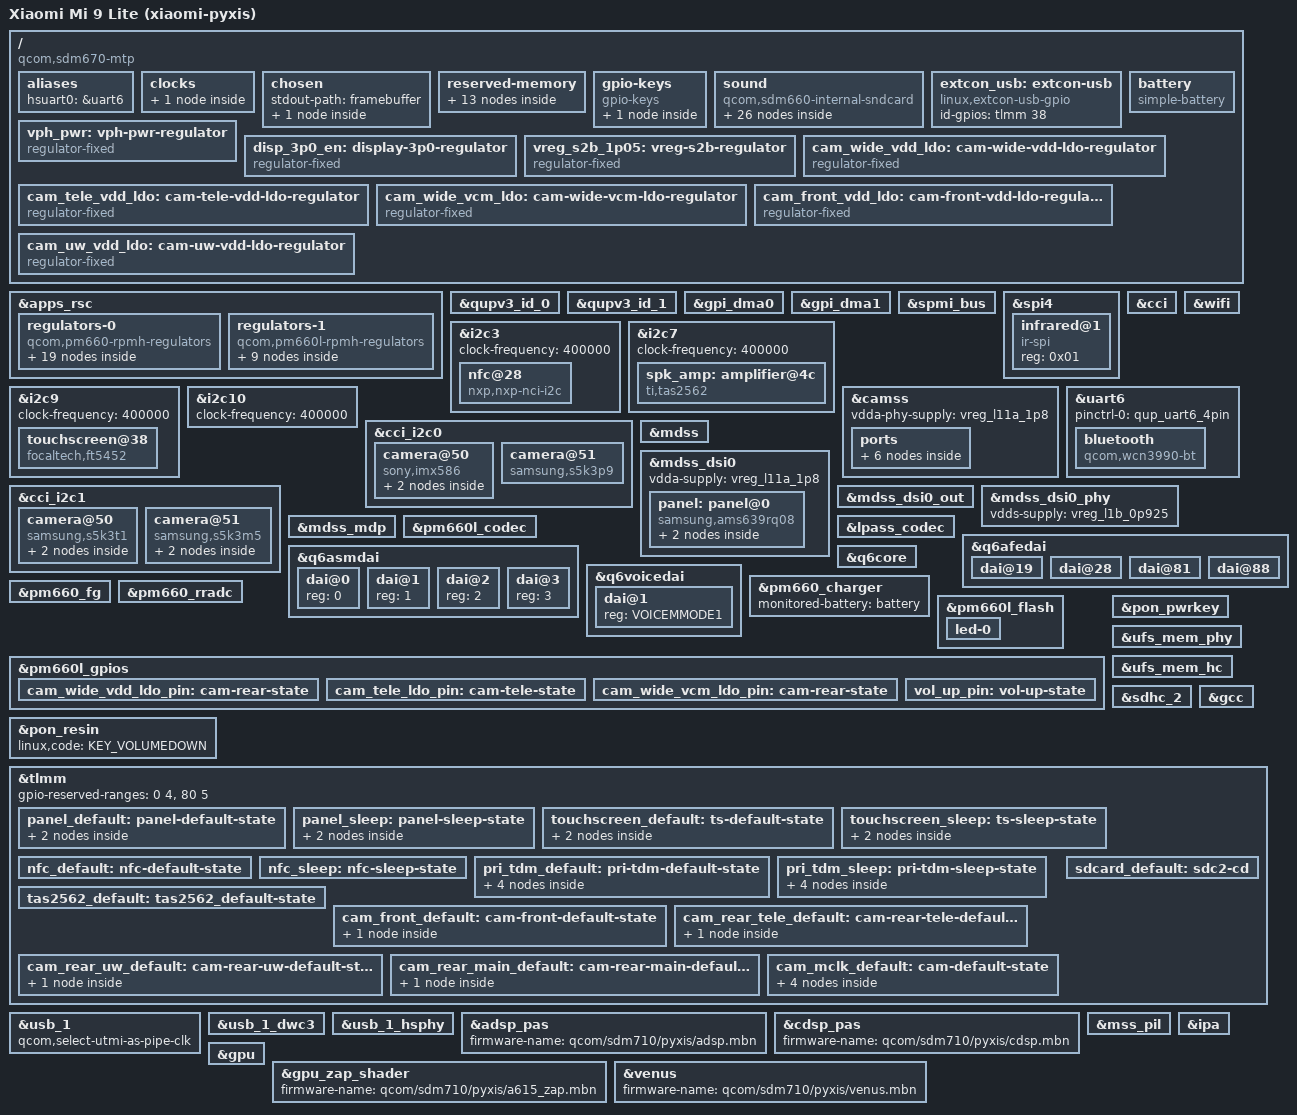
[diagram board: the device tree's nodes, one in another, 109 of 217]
// SPDX-License-Identifier: GPL-2.0
/*
 * Device tree for Xiaomi Mi 9 Lite (xiaomi-pyxis), based largely on
 * sdm670-google-sargo and downstream vendor kernel.
 *
 * Copyright (c) 2026, The Linux Foundation. All rights reserved.
*/

/dts-v1/;
#include <dt-bindings/firmware/qcom,scm.h>
#include <dt-bindings/gpio/gpio.h>
#include <dt-bindings/input/input.h>
#include <dt-bindings/leds/common.h>
#include <dt-bindings/pinctrl/qcom,pmic-gpio.h>
#include <dt-bindings/power/qcom-rpmpd.h>
#include <dt-bindings/sound/qcom,q6afe.h>
#include <dt-bindings/sound/qcom,q6asm.h>
#include <dt-bindings/sound/qcom,q6voice.h>
#include "sdm710.dtsi"
#include "pm660.dtsi"
#include "pm660l.dtsi"

/delete-node/ &xbl_mem;
/delete-node/ &wlan_msa_mem;
/delete-node/ &cdsp_mem;
/delete-node/ &mba_region;
/delete-node/ &adsp_mem;
/delete-node/ &ipa_fw_mem;
/delete-node/ &ipa_gsi_mem;
/delete-node/ &gpu_mem;
/delete-node/ &rmtfs_mem;

/ {
	model = "Xiaomi Mi 9 Lite (xiaomi-pyxis)";
	compatible = "qcom,sdm670-mtp", "qcom,sdm670", "qcom,mtp";
	qcom,msm-id = <0x360 0 393 0>;
	qcom,board-id = <35 0>;
	chassis-type = "handset";

	aliases {
		hsuart0 = &uart6;
	};

	clocks {
		int_cdc_bclk: int-cdc-bclk {
			compatible = "fixed-clock";
			#clock-cells = <0>;
			clock-frequency = <1536000>;
		};
	};

	chosen {
		stdout-path = "framebuffer";
		#address-cells = <2>;
		#size-cells = <2>;
		ranges;

		framebuffer: framebuffer@9c000000 {
			compatible = "simple-framebuffer";
			reg = <0 0x9c000000 0 (1080 * 2340 * 4)>;
			width = <1080>;
			height = <2340>;
			stride = <(1080 * 4)>;
			format = "a8r8g8b8";
			status = "okay";
		};
	};

	reserved-memory {
		#address-cells = <2>;
		#size-cells = <2>;

		xbl_mem: memory@85e00000 {
			reg = <0 0x85e00000 0 0x1c0000>;
			no-map;
		};

		// Looks like this is needed to avoid random crashes...
		removed_region: removed-region {
			reg = <0 0x85fc0000 0 0x4b40000>;
			no-map;
		};

		wlan_msa_mem: wlan-msa@93300000 {
			reg = <0 0x93300000 0 0x100000>;
			no-map;
		};

		cdsp_mem: cdsp@93400000 {
			reg = <0 0x93400000 0 0x1e00000>;
			no-map;
		};

		mba_region: mba@95200000 {
			reg = <0 0x95200000 0 0x200000>;
			no-map;
		};

		adsp_mem: adsp@95400000 {
			reg = <0 0x95400000 0 0x2200000>;
			no-map;
		};

		ipa_fw_mem: ipa-fw@97600000 {
			reg = <0 0x97600000 0 0x10000>;
			no-map;
		};

		ipa_gsi_mem: ipa-gsi@97610000 {
			reg = <0 0x97610000 0 0x5000>;
			no-map;
		};

		gpu_mem: gpu@97615000 {
			reg = <0 0x97615000 0 0x2000>;
			no-map;
		};

		fb_mem: framebuffer@9c000000 {
			reg = <0 0x9c000000 0 0x2300000>;
			no-map;
		};

		rmtfs_lower_guard: rmtfs-lower-guard@fc200000 {
			reg = <0 0xfc200000 0 0x1000>;
			no-map;
		};

		rmtfs_mem: rmtfs-mem@fc201000 {
			compatible = "qcom,rmtfs-mem";
			reg = <0 0xfc201000 0 0x200000>;
			no-map;
			qcom,client-id = <1>;
			qcom,vmid = <QCOM_SCM_VMID_MSS_MSA>;
		};

		rmtfs_upper_guard: rmtfs-upper-guard@fc401000 {
			reg = <0 0xfc401000 0 0x1000>;
			no-map;
		};
	};

	gpio-keys {
		compatible = "gpio-keys";
		autorepeat;

		pinctrl-names = "default";
		pinctrl-0 = <&vol_up_pin>;

		key-vol-up {
			label = "Volume Up";
			linux,code = <KEY_VOLUMEUP>;
			gpios = <&pm660l_gpios 7 GPIO_ACTIVE_LOW>;
		};
	};

	// AUDIO: WIP
	sound: sound {
		compatible = "qcom,sdm660-internal-sndcard";
		model = "Xiaomi Mi 9 Lite";

		pinctrl-names = "default";
		pinctrl-0 = <&cdc_pdm_default>,
			<&cdc_dmic_default>,
			<&pri_tdm_default>;

		audio-routing = "Analog PDM_RX1", "Digital PDM_RX1",
			"Analog PDM_RX2", "Digital PDM_RX2",
			"Analog PDM_RX3", "Digital PDM_RX3",
			"Digital LPASS_PDM_TX", "Analog PDM_TX",
			"Analog AMIC2", "Analog MIC BIAS External2",
			"Stereo1 DMIC Mux", "Analog MIC BIAS Internal1";

		mm1-dai-link {
			link-name = "MultiMedia1";

			cpu {
				sound-dai = <&q6asmdai MSM_FRONTEND_DAI_MULTIMEDIA1>;
			};
		};

		mm2-dai-link {
			link-name = "MultiMedia2";

			cpu {
				sound-dai = <&q6asmdai MSM_FRONTEND_DAI_MULTIMEDIA2>;
			};
		};

		mm3-dai-link {
			link-name = "MultiMedia3";

			cpu {
				sound-dai = <&q6asmdai MSM_FRONTEND_DAI_MULTIMEDIA3>;
			};
		};

		mm4-dai-link {
			link-name = "MultiMedia4";

			cpu {
				sound-dai = <&q6asmdai MSM_FRONTEND_DAI_MULTIMEDIA4>;
			};
		};

		voicemmode1-dai-link {
			link-name = "VoiceMMode1";

			cpu {
				sound-dai = <&q6voicedai VOICEMMODE1>;
			};
		};

		pri-tdm-tx-link {
			link-name = "Primary TDM0 Capture";

			cpu {
				sound-dai = <&q6afedai PRIMARY_TDM_TX_0>;
			};

			platform {
				sound-dai = <&q6routing>;
			};

			codec {
				sound-dai = <&spk_amp 0>;
			};
		};

		sec-tdm-rx-link {
			link-name = "Secondary TDM0 Playback";

			cpu {
				sound-dai = <&q6afedai SECONDARY_TDM_RX_0>;
			};

			platform {
				sound-dai = <&q6routing>;
			};

			codec {
				sound-dai = <&spk_amp 0>;
			};
		};

		int0-mi2s-rx-link {
			link-name = "Internal MI2S Playback";

			cpu {
				sound-dai = <&q6afedai INT0_MI2S_RX>;
			};

			platform {
				sound-dai = <&q6routing>;
			};

			codec {
				sound-dai = <&pm660l_codec 0>, <&lpass_codec 0>;
			};
		};

		int3-mi2s-tx-link {
				link-name = "Internal MI2S Capture";

			cpu {
				sound-dai = <&q6afedai INT3_MI2S_TX>;
			};

			platform {
				sound-dai = <&q6routing>;
			};

			codec {
				sound-dai = <&pm660l_codec 1>, <&lpass_codec 1>;
			};
		};
};

	extcon_usb: extcon-usb {
		compatible = "linux,extcon-usb-gpio";
		id-gpios = <&tlmm 38 GPIO_ACTIVE_HIGH>;
	};

	battery: battery {
		compatible = "simple-battery";
		voltage-min-design-microvolt = <3312000>;
		voltage-max-design-microvolt = <4400000>;
	};

	/* Regulators */
	vph_pwr: vph-pwr-regulator {
		compatible = "regulator-fixed";
		regulator-name = "vph_pwr";
		regulator-min-microvolt = <3312000>;
		regulator-max-microvolt = <3312000>;
		regulator-always-on;
		regulator-boot-on;
	};

	disp_3p0_en: display-3p0-regulator {
		compatible = "regulator-fixed";
		regulator-name = "disp_3p0_en";
		gpios = <&tlmm 76 GPIO_ACTIVE_HIGH>;
		enable-active-high;
		regulator-boot-on;
	};

	vreg_s2b_1p05: vreg-s2b-regulator {
		compatible = "regulator-fixed";
		regulator-name = "vreg_s2b";
		regulator-min-microvolt = <1050000>;
		regulator-max-microvolt = <1050000>;
	};

	/* Camera sensors */
	// IMX586: DVDD, AVDD
	cam_wide_vdd_ldo: cam-wide-vdd-ldo-regulator {
		compatible = "regulator-fixed";
		regulator-name = "cam_wide_vdd_ldo";
		regulator-min-microvolt = <1352000>;
		regulator-max-microvolt = <1352000>;
		regulator-enable-ramp-delay = <135>;

		gpios = <&pm660l_gpios 2 GPIO_ACTIVE_HIGH>;
		enable-active-high;

		pinctrl-0 = <&cam_wide_vdd_ldo_pin>;
		pinctrl-names = "default";
	};

	// S5K3M5: AVDD
	cam_tele_vdd_ldo: cam-tele-vdd-ldo-regulator {
		compatible = "regulator-fixed";
		regulator-name = "cam_tele_vdd_ldo";
		regulator-min-microvolt = <2800000>;
		regulator-max-microvolt = <2800000>;
		regulator-enable-ramp-delay = <135>;

		gpios = <&pm660l_gpios 3 GPIO_ACTIVE_HIGH>;
		enable-active-high;

		pinctrl-0 = <&cam_tele_ldo_pin>;
		pinctrl-names = "default";
	};

	// IMX586: VCM (Autofocus)
	cam_wide_vcm_ldo: cam-wide-vcm-ldo-regulator {
		compatible = "regulator-fixed";
		regulator-name = "cam_wide_vcm_ldo";
		regulator-min-microvolt = <2800000>;
		regulator-max-microvolt = <2800000>;
		regulator-enable-ramp-delay = <135>;

		gpios = <&pm660l_gpios 4 GPIO_ACTIVE_HIGH>;
		enable-active-high;

		pinctrl-0 = <&cam_wide_vcm_ldo_pin>;
		pinctrl-names = "default";
	};

	// S5K3T1: AVDD, DVDD
	cam_front_vdd_ldo: cam-front-vdd-ldo-regulator {
		compatible = "regulator-fixed";
		regulator-name = "cam_front_vdd_ldo";
		gpios = <&tlmm 8 GPIO_ACTIVE_HIGH>;
		enable-active-high;
	};

	// S5K3P9: DVDD
	cam_uw_vdd_ldo: cam-uw-vdd-ldo-regulator {
		compatible = "regulator-fixed";
		regulator-name = "cam_uw_vdd_ldo";
		gpios = <&tlmm 27 GPIO_ACTIVE_HIGH>;
		enable-active-high;
	};
};

/* Regulators */
&apps_rsc {
	regulators-0 {
		compatible = "qcom,pm660-rpmh-regulators";
		qcom,pmic-id = "a";

		vdd-s1-supply = <&vph_pwr>;
		vdd-s2-supply = <&vph_pwr>;
		vdd-s3-supply = <&vph_pwr>;
		vdd-s4-supply = <&vph_pwr>;
		vdd-s5-supply = <&vph_pwr>;
		vdd-s6-supply = <&vph_pwr>;

		vdd-l1-l6-l7-supply = <&vreg_s6a_0p87>;
		vdd-l2-l3-supply = <&vreg_s2b_1p05>;
		vdd-l5-supply = <&vreg_s2b_1p05>;
		vdd-l8-l9-l10-l11-l12-l13-l14-supply = <&vreg_s4a_2p04>;
		vdd-l15-l16-l17-l18-l19-supply = <&vreg_bob>;

		/*
		 * S1A (FTAPC0), S2A (FTAPC1), S3A (HFAPC1) are managed
		 * by the Core Power Reduction hardened (CPRh) and the
		 * Operating State Manager (OSM) HW automatically.
		 */

		vreg_s4a_2p04: smps4 {
			regulator-min-microvolt = <1808000>;
			regulator-max-microvolt = <2040000>;
			regulator-enable-ramp-delay = <200>;
		};

		vreg_s6a_0p87: smps6 {
			regulator-min-microvolt = <1224000>;
			regulator-max-microvolt = <1352000>;
			regulator-enable-ramp-delay = <150>;
		};

		/* LDOs */
		vreg_l1a_1p225: ldo1 {
			regulator-min-microvolt = <1200000>;
			regulator-max-microvolt = <1250000>;
			regulator-enable-ramp-delay = <250>;
		};

		vreg_l2a_1p0: ldo2 {
			regulator-min-microvolt = <1000000>;
			regulator-max-microvolt = <1000000>;
			regulator-enable-ramp-delay = <250>;
		};

		vreg_l3a_1p0: ldo3 {
			regulator-min-microvolt = <1000000>;
			regulator-max-microvolt = <1000000>;
			regulator-enable-ramp-delay = <250>;
		};

		// Possibly unused according to stock (dumped) DT...
		vreg_l5a_0p848: ldo5 {
			regulator-min-microvolt = <800000>;
			regulator-max-microvolt = <800000>;
			regulator-enable-ramp-delay = <250>;
		};

		vreg_l6a_1p3: ldo6 {
			regulator-min-microvolt = <1248000>;
			regulator-max-microvolt = <1304000>;
			regulator-enable-ramp-delay = <250>;
		};

		vreg_l7a_1p2: ldo7 {
			regulator-min-microvolt = <1200000>;
			regulator-max-microvolt = <1200000>;
			regulator-enable-ramp-delay = <250>;
		};

		vreg_l8a_1p8: ldo8 {
			regulator-min-microvolt = <1800000>;
			regulator-max-microvolt = <1800000>;
			regulator-enable-ramp-delay = <250>;
			regulator-always-on;
		};

		vreg_l9a_1p8: ldo9 {
			regulator-min-microvolt = <1800000>;
			regulator-max-microvolt = <1800000>;
			regulator-enable-ramp-delay = <250>;
		};

		vreg_l10a_1p8: ldo10 {
			regulator-min-microvolt = <1800000>;
			regulator-max-microvolt = <1800000>;
			regulator-enable-ramp-delay = <250>;
		};

		vreg_l11a_1p8: ldo11 {
			regulator-min-microvolt = <1800000>;
			regulator-max-microvolt = <1800000>;
			regulator-enable-ramp-delay = <250>;
		};

		vreg_l12a_1p8: ldo12 {
			regulator-min-microvolt = <1800000>;
			regulator-max-microvolt = <1800000>;
			regulator-enable-ramp-delay = <250>;
		};

		vreg_l13a_1p8: ldo13 {
			regulator-min-microvolt = <1800000>;
			regulator-max-microvolt = <1800000>;
			regulator-enable-ramp-delay = <250>;
		};

		vreg_l14a_1p8: ldo14 {
			regulator-min-microvolt = <1800000>;
			regulator-max-microvolt = <1800000>;
			regulator-enable-ramp-delay = <250>;
		};

		vreg_l15a_1p8: ldo15 {
			regulator-min-microvolt = <1800000>;
			regulator-max-microvolt = <2950000>;
			regulator-enable-ramp-delay = <250>;
		};

		// Stock sets it to 2700000, but range seems unsupported...
		vreg_l16a_2p7: ldo16 {
			regulator-min-microvolt = <2696000>;
			regulator-max-microvolt = <2696000>;
			regulator-enable-ramp-delay = <250>;
		};

		vreg_l17a_1p8: ldo17 {
			regulator-min-microvolt = <1800000>;
			regulator-max-microvolt = <2950000>;
			regulator-enable-ramp-delay = <250>;
		};

		vreg_l19a_3p3: ldo19 {
			regulator-min-microvolt = <3000000>;
			regulator-max-microvolt = <3312000>;
			regulator-enable-ramp-delay = <250>;
		};
	};

	regulators-1 {
		compatible = "qcom,pm660l-rpmh-regulators";
		qcom,pmic-id = "b";

		vdd-s1-supply = <&vph_pwr>;
		vdd-s2-supply = <&vph_pwr>;
		vdd-s3-s4-supply = <&vph_pwr>;
		vdd-s5-supply = <&vph_pwr>;

		vdd-l1-l9-l10-supply = <&vreg_s2b_1p05>;
		vdd-l2-supply = <&vreg_bob>;
		vdd-l3-l5-l7-l8-supply = <&vreg_bob>;
		vdd-l4-l6-supply = <&vreg_bob>;
		vdd-bob-supply = <&vph_pwr>;

		/* LDOs */
		vreg_l1b_0p925: ldo1 {
			regulator-min-microvolt = <880000>;
			regulator-max-microvolt = <900000>;
			regulator-enable-ramp-delay = <250>;
		};

		vreg_l2b_2p95: ldo2 {
			regulator-min-microvolt = <1800000>;
			regulator-max-microvolt = <2960000>;
			regulator-enable-ramp-delay = <250>;
		};

		vreg_l3b_3p0: ldo3 {
			regulator-min-microvolt = <2800000>;
			regulator-max-microvolt = <3008000>;
			regulator-enable-ramp-delay = <250>;
		};

		vreg_l4b_2p95: ldo4 {
			regulator-min-microvolt = <2960000>;
			regulator-max-microvolt = <2960000>;
			regulator-enable-ramp-delay = <250>;
		};

		vreg_l5b_2p95: ldo5 {
			regulator-min-microvolt = <2960000>;
			regulator-max-microvolt = <2960000>;
			regulator-enable-ramp-delay = <250>;
		};

		vreg_l6b_3p3: ldo6 {
			regulator-min-microvolt = <3008000>;
			regulator-max-microvolt = <3300000>;
			regulator-enable-ramp-delay = <250>;
		};

		vreg_l7b_3p125: ldo7 {
			regulator-min-microvolt = <3088000>;
			regulator-max-microvolt = <3100000>;
			regulator-enable-ramp-delay = <250>;
		};

		vreg_l8b_3p3: ldo8 {
			regulator-min-microvolt = <3300000>;
			regulator-max-microvolt = <3312000>;
			regulator-enable-ramp-delay = <250>;
		};

		/*
		 * Downstream specifies a fixed voltage of 3.312 V, but the
		 * PMIC4 BOB ranges don't support that. Widen the range a
		 * little to avoid adding a new BOB regulator type.
		 */
		vreg_bob: bob {
			regulator-min-microvolt = <3296000>;
			regulator-max-microvolt = <3328000>;
			regulator-enable-ramp-delay = <500>;
		};
	};
};

/* Enable i2c/spi blocks */
&qupv3_id_0 {
	status = "okay";
};

&qupv3_id_1 {
	status = "okay";
};

&gpi_dma0 {
	status = "okay";
};

&gpi_dma1 {
	status = "okay";
};

&spmi_bus {
	status = "okay";
};

/* IR blaster */
&spi4 {
	status = "okay";

	infrared@1 {
		compatible = "ir-spi";
		reg = <0x01>;
	};
};

/* NFC */
&i2c3 {
	status = "okay";
	clock-frequency = <400000>;

	nfc@28 {
		compatible = "nxp,nxp-nci-i2c";
		reg = <0x28>;

		interrupts-extended = <&tlmm 44 IRQ_TYPE_EDGE_RISING>;
		enable-gpios = <&tlmm 12 GPIO_ACTIVE_HIGH>;
		firmware-gpios = <&tlmm 43 GPIO_ACTIVE_HIGH>;

		pinctrl-names = "default", "sleep";
		pinctrl-0 = <&nfc_default>;
		pinctrl-1 = <&nfc_sleep>;
	};
};

/* Audio amp */
&i2c7 {
	status = "okay";
	clock-frequency = <400000>;

	spk_amp: amplifier@4c {
		compatible = "ti,tas2562";
		reg = <0x4c>;
		#sound-dai-cells = <1>;

		interrupts-extended = <&tlmm 96 IRQ_TYPE_EDGE_FALLING>;
		shutdown-gpios = <&tlmm 95 GPIO_ACTIVE_HIGH>;

		vdd-supply = <&vreg_l13a_1p8>;
	};
};


/* Touchscreen */
&i2c9 {
	status = "okay";
	clock-frequency = <400000>;

	touchscreen@38 {
		compatible = "focaltech,ft5452";
		reg = <0x38>;

		interrupts-extended = <&tlmm 125 IRQ_TYPE_EDGE_FALLING>;
		reset-gpios = <&tlmm 5 GPIO_ACTIVE_LOW>;

		pinctrl-names = "default", "sleep";
		pinctrl-0 = <&touchscreen_default>;
		pinctrl-1 = <&touchscreen_sleep>;

		vcc-supply = <&vreg_l8b_3p3>;
		iovcc-supply = <&vreg_l13a_1p8>;

		touchscreen-size-x = <1080>;
		touchscreen-size-y = <2340>;
	};
};

&i2c10 {
	status = "okay";
	clock-frequency = <400000>;

	// smb1355@8
	// smb1355@c
};

/* Xiaomi did cursed stuff with MIPI switch to switch between front and
 * ultrawide cameras. CSI2 MIPI switch is controlled by SoC GPIO_25 */

/* CSI_0: Sony IMX586. CAM_W_MCLK0 (GPIO_13), I2C0.
 * CSI_1: Two cameras hooked up via TS5MP646 MIPI switch:
 * - Port A: Front - Samsung S5K3T1. CAM_F_MCLK2 (GPIO_15), I2C1.
 * - Port B: Ultrawide - Samsung S5K3P9. CAM_U_MCLK3 (GPIO_16), I2C0.
 * CSI_2: Samsung S5K3M5. CAM_T_MCLK1 (GPIO_13), I2C1. Only a single-lane. */

/* Camera subsystem */
&camss {
	vdda-phy-supply = <&vreg_l11a_1p8>;
	status = "okay";

	ports {
		port@0 {
			camss_endpoint0: endpoint {
				clock-lanes = <7>;
				data-lanes = <0 1 2 3>;
				remote-endpoint = <&cam_rear_main_endpoint>;
			};
		};

		port@1 {
			camss_endpoint1: endpoint {
				clock-lanes = <7>;
				data-lanes = <0 1 2 3>;
				remote-endpoint = <&cam_dual_endpoint>;
			};
		};

		port@2 {
			camss_endpoint2: endpoint {
				clock-lanes = <3>;
				data-lanes = <0>;
				remote-point = <&cam_rear_tele_endpoint>;
			};
		};
	};
};

&cci {
	pinctrl-names = "default", "sleep";
	pinctrl-0 = <&cci0_default &cci1_default &cam_mclk_default>;
	pinctrl-1 = <&cci0_sleep &cci1_sleep>;

	status = "okay";
};

&cci_i2c0 {
	camera@50 {
		compatible = "sony,imx586";
		reg = <0x50>;

		clocks = <&camcc CAM_CC_MCLK0_CLK>;
		clock-names = "xvclk";
		clock-frequency = <24000000>;
		assigned-clocks = <&camcc CAM_CC_MCLK0_CLK>;
		assigned-clock-rates = <24000000>;

		reset-gpios = <&tlmm 30 GPIO_ACTIVE_LOW>;

		pinctrl-names = "default";
		pinctrl-0 = <&cam_rear_main_default>;

		port {
			cam_rear_main_endpoint: endpoint {
				data-lanes = <0 1 2 3>;
				link-frequencies = /bits/ 64 <321000000 636000000>;
				remote-endpoint = <&camss_endpoint0>;
			};
		};
	};

	camera@51 {
		compatible = "samsung,s5k3p9";
		reg = <0x51>;

		clocks = <&camcc CAM_CC_MCLK3_CLK>;
		clock-names = "mclk";
		clock-frequency = <19200000>;
		assigned-clocks = <&camcc CAM_CC_MCLK3_CLK>;
		assigned-clock-rates = <24000000>;

		reset-gpios = <&tlmm 24 GPIO_ACTIVE_HIGH>;

		pinctrl-names = "default";
		pinctrl-0 = <&cam_rear_uw_default>;

//		port {
//			cam_dual_endpoint: endpoint {
//				data-lanes = <0 1 2 3>;
//				link-frequencies = /bits/ 64 <360000000>;
//				remote-endpoint = <&camss_endpoint2>;
//		};
	};
};

&cci_i2c1 {
	camera@50 {
		compatible = "samsung,s5k3t1";
		reg = <0x50>;

		clocks = <&camcc CAM_CC_MCLK2_CLK>;
		clock-names = "mclk";
		clock-frequency = <19200000>;
		assigned-clocks = <&camcc CAM_CC_MCLK2_CLK>;
		assigned-clock-rates = <24000000>;

		reset-gpios = <&tlmm 9 GPIO_ACTIVE_HIGH>;

		pinctrl-names = "default";
		pinctrl-0 = <&cam_front_default>;

		port {
			cam_dual_endpoint: endpoint {
				data-lanes = <0 1 2 3>;
				link-frequencies = /bits/ 64 <360000000>;
				remote-endpoint = <&camss_endpoint1>;
			};
		};
	};

	camera@51 {
		compatible = "samsung,s5k3m5";
		reg = <0x51>;

		clocks = <&camcc CAM_CC_MCLK1_CLK>;
		clock-names = "mclk";
		clock-frequency = <19200000>;
		assigned-clocks = <&camcc CAM_CC_MCLK1_CLK>;
		assigned-clock-rates = <24000000>;

		reset-gpios = <&tlmm 23 GPIO_ACTIVE_HIGH>;

		pinctrl-names = "default";
		pinctrl-0 = <&cam_rear_tele_default>;

		port {
			cam_rear_tele_endpoint: endpoint {
				data-lanes = <0 1 2 3>;
				link-frequencies = /bits/ 64 <360000000>;
				remote-endpoint = <&camss_endpoint2>;
			};
		};
	};
};

/* WiFi and Bluetooth */
&wifi {
	status = "okay";

	vdd-0.8-cx-mx-supply = <&vreg_l5a_0p848>;
	vdd-1.8-xo-supply = <&vreg_l9a_1p8>;
	vdd-1.3-rfa-supply = <&vreg_l6a_1p3>;
	vdd-3.3-ch0-supply = <&vreg_l19a_3p3>;

	qcom,snoc-host-cap-8bit-quirk;
};

&uart6 {
	pinctrl-0 = <&qup_uart6_4pin>;
	status = "okay";

	bluetooth {
		compatible = "qcom,wcn3990-bt";
		vddio-supply = <&vph_pwr>;
		vddxo-supply = <&vreg_l9a_1p8>;
		vddrf-supply = <&vreg_l6a_1p3>;
		vddch0-supply = <&vreg_l19a_3p3>;
		max-speed = <3200000>;
	};
};

/* Display Subsystem */
&mdss {
	status = "okay";
};

&mdss_dsi0 {
	status = "okay";
	vdda-supply = <&vreg_l11a_1p8>;

	panel: panel@0 {
		status = "okay";
		compatible = "samsung,ams639rq08";
		reg = <0>;

		te-gpios = <&tlmm 10 GPIO_ACTIVE_LOW>;
		reset-gpios = <&tlmm 75 GPIO_ACTIVE_LOW>;

		pinctrl-names = "default", "sleep";
		pinctrl-0 = <&panel_default>;
		pinctrl-1 = <&panel_sleep>;

		vddio-supply = <&disp_3p0_en>;
		vdd3p3-supply = <&vreg_l8b_3p3>;

		port {
			panel_in: endpoint {
				remote-endpoint = <&mdss_dsi0_out>;
			};
		};
	};
};

&mdss_dsi0_out {
	data-lanes = <0 1 2 3>;
	remote-endpoint = <&panel_in>;
};

&mdss_dsi0_phy {
	status = "okay";
	vdds-supply = <&vreg_l1b_0p925>;
};

&mdss_mdp {
	status = "okay";
};

/* Audio - WIP */
&pm660l_codec {
	vdd-cdc-io-supply = <&vreg_l13a_1p8>;
	vdd-cdc-tx-rx-cx-supply = <&vreg_l1b_0p925>;
	vdd-micbias-supply = <&vreg_l3b_3p0>;

	qcom,mbhc-vthreshold-low = <75 150 237 437 437>;
	qcom,mbhc-vthreshold-high = <75 150 237 437 437>;

	status = "okay";
};

&lpass_codec {
	clocks = <&q6afecc LPASS_CLK_ID_INT_MCLK_0 LPASS_CLK_ATTRIBUTE_COUPLE_NO>,
	         <&int_cdc_bclk>;
	clock-names = "mclk", "ahbix-clk";

	assigned-clocks = <&q6afecc LPASS_CLK_ID_INT_MCLK_0 LPASS_CLK_ATTRIBUTE_COUPLE_NO>;
	assigned-clock-rates = <9600000>;

	status = "okay";
};

//&lpi_tlmm {
//	status = "okay";
//};

&q6afedai {
	dai@19 {
		reg = <PRIMARY_TDM_TX_0>;

		qcom,tdm-sync-mode = <0>;
		qcom,tdm-sync-src = <1>;
		qcom,tdm-data-out = <0>;
		qcom,tdm-invert-sync = <0>;
		qcom,tdm-data-delay = <1>;
		qcom,tdm-data-align = <0>;
	};

	dai@28 {
		reg = <SECONDARY_TDM_RX_0>;

		qcom,tdm-sync-mode = <0>;
		qcom,tdm-sync-src = <1>;
		qcom,tdm-data-out = <0>;
		qcom,tdm-invert-sync = <0>;
		qcom,tdm-data-delay = <1>;
		qcom,tdm-data-align = <0>;
	};

	dai@81 {
		reg = <INT0_MI2S_RX>;
		qcom,sd-lines = <0 1>;
	};

	dai@88 {
		reg = <INT3_MI2S_TX>;
		qcom,sd-lines = <0 1>;
	};
};

&q6asmdai {
	dai@0 {
		reg = <0>;
	};

	dai@1 {
		reg = <1>;
	};

	dai@2 {
		reg = <2>;
	};

	dai@3 {
		reg = <3>;
	};
};

&q6core {
		qcom,acdb-name = "qcom/sdm710/pyxis/Global_cal.acdb";
};

&q6voicedai {
	dai@1 {
		reg = <VOICEMMODE1>;
	};
};

/* PMIC */
&pm660_charger {
	monitored-battery = <&battery>;
	status = "okay";
};

&pm660_fg {
	monitored-battery = <&battery>;
	power-supplies = <&pm660_charger>;
	status = "okay";
};

&pm660_rradc {
	status = "okay";
};

&pm660l_flash {
	status = "okay";

	led-0 {
		function = LED_FUNCTION_FLASH;
		color = <LED_COLOR_ID_WHITE>;
		led-sources = <1>, <2>;
		led-max-microamp = <350000>;
		flash-max-microamp = <1000000>;
		flash-max-timeout-us = <1280000>;
	};
};

&pm660l_gpios {
	cam_wide_vdd_ldo_pin: cam-rear-state {
		pins = "gpio2";
		function = "normal";
		power-source = <PM8941_GPIO_VPH>;
		output-low;
	};

	cam_tele_ldo_pin: cam-tele-state {
		pins = "gpio3";
		function = "normal";
		power-source = <PM8941_GPIO_VPH>;
		output-low;
	};

	cam_wide_vcm_ldo_pin: cam-rear-state {
		pins = "gpio4";
		function = "normal";
		power-source = <PM8941_GPIO_VPH>;
		output-low;
	};

	vol_up_pin: vol-up-state {
		pins = "gpio7";
		function = "normal";
		qcom,drive-strength = <PMIC_GPIO_STRENGTH_NO>;
		input-enable;
		bias-pull-up;
	};
};

&pon_pwrkey {
	status = "okay";
};

&pon_resin {
	linux,code = <KEY_VOLUMEDOWN>;
	status = "okay";
};

/* Storage: UFS */
&ufs_mem_phy {
	status = "okay";

	vdda-phy-supply = <&vreg_l1b_0p925>;
	vdda-pll-supply = <&vreg_l1a_1p225>;
};

&ufs_mem_hc {
	status = "okay";

	reset-gpios = <&tlmm 150 GPIO_ACTIVE_LOW>;

	vcc-supply = <&vreg_l4b_2p95>;
	vccq2-supply = <&vreg_l8b_3p3>;
};

/* Storage: MicroSD slot */
&sdhc_2 {
	status = "okay";

	vmmc-supply = <&vreg_l5b_2p95>;
	vqmmc-supply = <&vreg_l2b_2p95>;

	cd-gpios = <&tlmm 126 GPIO_ACTIVE_HIGH>;

	pinctrl-0 = <&sdcard_default>;
	pinctrl-names = "default";

	no-sdio;
	no-mmc;
};

/* Global Clock Controller */
&gcc {
	protected-clocks = <GCC_QSPI_CORE_CLK>,
		<GCC_QSPI_CORE_CLK_SRC>,
		<GCC_QSPI_CNOC_PERIPH_AHB_CLK>;
};

/* SoC GPIO aka pinctrl */
&tlmm {
	gpio-reserved-ranges = <0 4>, <80 5>;

	/* GPIOs for display panel */
	panel_default: panel-default-state {
		te-pins {
			pins = "gpio10";
			function = "mdp_vsync";
			drive-strength = <2>;
			bias-pull-down;
		};

		reset-pins {
			pins = "gpio75";
			function = "gpio";
			drive-strength = <8>;
			bias-disable;
		};
	};

	panel_sleep: panel-sleep-state {
		te-pins {
			pins = "gpio10";
			function = "mdp_vsync";
			drive-strength = <2>;
			bias-pull-down;
		};

		reset-pins {
			pins = "gpio75";
			function = "gpio";
			drive-strength = <8>;
			bias-disable;
		};
	};

	/* GPIOs for touchscreen */
	touchscreen_default: ts-default-state {
		ts-irq-pins {
			pins = "gpio125";
			function = "gpio";
			drive-strength = <10>;
			bias-pull-up;
		};

		ts-reset-pins {
			pins = "gpio5";
			function = "gpio";
			drive-strength = <10>;
			bias-pull-up;
		};
	};

	touchscreen_sleep: ts-sleep-state {
		ts-irq-pins {
			pins = "gpio125";
			function = "gpio";
			drive-strength = <10>;
			bias-disable;
		};

		ts-reset-pins {
			pins = "gpio5";
			function = "gpio";
			drive-strength = <10>;
			bias-disable;
		};
	};

	/* GPIOs for NFC */
	nfc_default: nfc-default-state {
		pins = "gpio12", "gpio43", "gpio44", "gpio116";
		function = "gpio";
		drive-strength = <2>;
		bias-pull-up;
};

	nfc_sleep: nfc-sleep-state {
		pins = "gpio12", "gpio43", "gpio44", "gpio116";
		function = "gpio";
		drive-strength = <2>;
		bias-disable;
	};

	/* GPIOs for Audio Codec */
	pri_tdm_default: pri-tdm-default-state {
		misc-pins {
			pins = "gpio65";
			function = "pri_mi2s";
			drive-strength = <8>;
		};

		ws-pins {
			pins = "gpio66";
			function = "pri_mi2s_ws";
			drive-strength = <8>;
		};

		dout-pins {
			pins = "gpio67";
			function = "pri_mi2s";
			drive-strength = <8>;
		};

		din-pins {
			pins = "gpio68";
			function = "pri_mi2s";
			drive-strength = <8>;
		};
	};

	pri_tdm_sleep: pri-tdm-sleep-state {
		misc-pins {
			pins = "gpio65";
			function = "pri_mi2s";
			drive-strength = <2>;
			bias-pull-down;
		};

		ws-pins {
			pins = "gpio66";
			function = "pri_mi2s_ws";
			drive-strength = <2>;
			bias-pull-down;
		};

		dout-pins {
			pins = "gpio67";
			function = "pri_mi2s";
			drive-strength = <2>;
			bias-pull-down;
		};

		din-pins {
			pins = "gpio68";
			function = "pri_mi2s";
			drive-strength = <2>;
			bias-pull-down;
		};
	};

	/* GPIOs for Speaker Amplifier */
	tas2562_default: tas2562_default-state {
		pins = "gpio95", "gpio96";
		function = "gpio";
		drive-strength = <2>;
	};

	/* GPIOs for Camera reset/power */
	cam_front_default: cam-front-default-state {
		pins = "gpio8";
		function = "gpio";
		drive-strength = <2>;
		bias-disable;

		reset-pins {
			pins = "gpio9";
			function = "gpio";
			drive-strength = <2>;
			input-enable;
		};
	};

	cam_rear_tele_default: cam-rear-tele-default-state {
		reset-pins {
			pins = "gpio23";
			function = "gpio";
			drive-strength = <2>;
			bias-disable;
		};
	};

	cam_rear_uw_default: cam-rear-uw-default-state {
		reset-pins {
			pins = "gpio24";
			function = "gpio";
			drive-strength = <2>;
			bias-disable;
		};
	};

	cam_rear_main_default: cam-rear-main-default-state {
		reset-pins {
			pins = "gpio30";
			function = "gpio";
			drive-strength = <2>;
			bias-disable;
		};
	};

	/* GPIOs for Camera MCLKs */
	cam_mclk_default: cam-default-state {
		// Main (IMX586)
		mclk0-pins {
			pins = "gpio13";
			function = "cam_mclk";
			drive-strength = <2>;
			bias-disable;
		};

		// Telephoto (S5K3M5)
		mclk1-pins {
			pins = "gpio14";
			function = "cam_mclk";
			drive-strength = <2>;
			bias-disable;
		};

		// Front (S5K3T1SP)
		mclk2-pins {
			pins = "gpio15";
			function = "cam_mclk";
			drive-strength = <2>;
			bias-disable;
		};

		// Ultrawide (S5K3P9)
		mclk3-pins {
			pins = "gpio16";
			function = "cam_mclk";
			drive-strength = <2>;
			bias-disable;
		};
	};

	/* MicroSD card-detect */
	sdcard_default: sdc2-cd {
		pins = "gpio126";
		function = "gpio";
		drive-strength = <2>;
		bias-pull-up;
	};
};

/* USB: Only USB2.0 because Xiaomi are cheapskates */
&usb_1 {
	status = "okay";
	qcom,select-utmi-as-pipe-clk;
};

&usb_1_dwc3 {
	dr_mode = "peripheral";
	extcon = <&extcon_usb>;
	phys = <&usb_1_hsphy>;
	phy-names = "usb2-phy";
	maximum-speed = "high-speed";

	/delete-property/ snps,dis_u2_susphy_quirk;
	/delete-property/ snps,dis_enblslpm_quirk;
};

&usb_1_hsphy {
	status = "okay";
	vdd-supply = <&vreg_l1b_0p925>;
	vdda-pll-supply = <&vreg_l10a_1p8>;
	vdda-phy-dpdm-supply = <&vreg_l7b_3p125>;
};

/* Remoteproc etc. */
&adsp_pas {
	status = "okay";
	firmware-name = "qcom/sdm710/pyxis/adsp.mbn";
};

&cdsp_pas {
	status = "okay";
	firmware-name = "qcom/sdm710/pyxis/cdsp.mbn";
};

&mss_pil {
	status = "okay";
	firmware-name = "qcom/sdm710/pyxis/mba.mbn",
			"qcom/sdm710/pyxis/modem.mbn";
};

&ipa {
	status = "okay";
	qcom,gsi-loader = "self";
	memory-region = <&ipa_fw_mem>;
	firmware-name = "qcom/sdm710/pyxis/ipa_fws.mbn";
};

&gpu {
	status = "okay";
};

&gpu_zap_shader {
	firmware-name = "qcom/sdm710/pyxis/a615_zap.mbn";
};

&venus {
	status = "okay";
	firmware-name = "qcom/sdm710/pyxis/venus.mbn";
};
